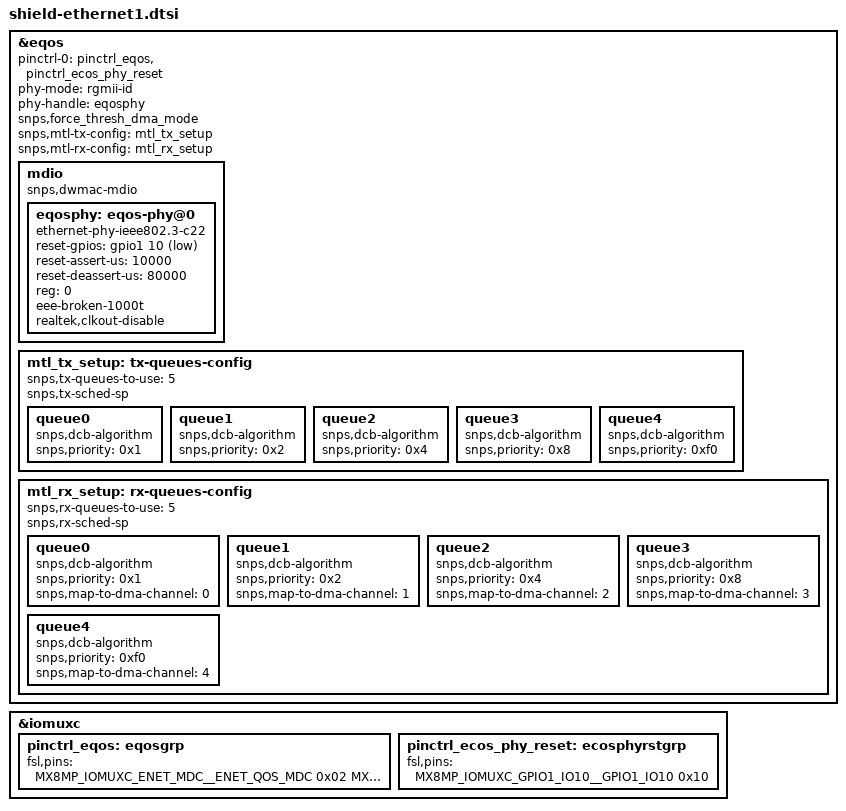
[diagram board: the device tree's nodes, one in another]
// SPDX-License-Identifier: (GPL-2.0+ OR MIT)
/*
 * Copyright 2025 CriticalShift
 */

&eqos {
	pinctrl-names = "default";
	pinctrl-0 = <&pinctrl_eqos>, <&pinctrl_ecos_phy_reset>;
	phy-mode = "rgmii-id";
	phy-handle = <&eqosphy>;
	snps,force_thresh_dma_mode;
	snps,mtl-tx-config = <&mtl_tx_setup>;
	snps,mtl-rx-config = <&mtl_rx_setup>;
	status = "okay";

	mdio {
		compatible = "snps,dwmac-mdio";
		#address-cells = <1>;
		#size-cells = <0>;

		eqosphy: eqos-phy@0 {
			compatible = "ethernet-phy-ieee802.3-c22";
			reset-gpios = <&gpio1 10 GPIO_ACTIVE_LOW>;
			reset-assert-us = <10000>;
			reset-deassert-us = <80000>;
			reg = <0>;
			eee-broken-1000t;
			realtek,clkout-disable;
		};
	};

	mtl_tx_setup: tx-queues-config {
		snps,tx-queues-to-use = <5>;
		snps,tx-sched-sp;
		queue0 {
			snps,dcb-algorithm;
			snps,priority = <0x1>;
		};
		queue1 {
			snps,dcb-algorithm;
			snps,priority = <0x2>;
		};
		queue2 {
			snps,dcb-algorithm;
			snps,priority = <0x4>;
		};
		queue3 {
			snps,dcb-algorithm;
			snps,priority = <0x8>;
		};
		queue4 {
			snps,dcb-algorithm;
			snps,priority = <0xf0>;
		};
	};

	mtl_rx_setup: rx-queues-config {
		snps,rx-queues-to-use = <5>;
		snps,rx-sched-sp;
		queue0 {
			snps,dcb-algorithm;
			snps,priority = <0x1>;
			snps,map-to-dma-channel = <0>;
		};
		queue1 {
			snps,dcb-algorithm;
			snps,priority = <0x2>;
			snps,map-to-dma-channel = <1>;
		};
		queue2 {
			snps,dcb-algorithm;
			snps,priority = <0x4>;
			snps,map-to-dma-channel = <2>;
		};
		queue3 {
			snps,dcb-algorithm;
			snps,priority = <0x8>;
			snps,map-to-dma-channel = <3>;
		};
		queue4 {
			snps,dcb-algorithm;
			snps,priority = <0xf0>;
			snps,map-to-dma-channel = <4>;
		};
	};
};

&iomuxc {
	pinctrl_eqos: eqosgrp {
		fsl,pins = <
			MX8MP_IOMUXC_ENET_MDC__ENET_QOS_MDC					0x02
			MX8MP_IOMUXC_ENET_MDIO__ENET_QOS_MDIO				0x02
			MX8MP_IOMUXC_ENET_RD0__ENET_QOS_RGMII_RD0			0x90
			MX8MP_IOMUXC_ENET_RD1__ENET_QOS_RGMII_RD1			0x90
			MX8MP_IOMUXC_ENET_RD2__ENET_QOS_RGMII_RD2			0x90
			MX8MP_IOMUXC_ENET_RD3__ENET_QOS_RGMII_RD3			0x90
			MX8MP_IOMUXC_ENET_RXC__CCM_ENET_QOS_CLOCK_GENERATE_RX_CLK	0x90
			MX8MP_IOMUXC_ENET_RX_CTL__ENET_QOS_RGMII_RX_CTL		0x90
			MX8MP_IOMUXC_ENET_TD0__ENET_QOS_RGMII_TD0			0x16
			MX8MP_IOMUXC_ENET_TD1__ENET_QOS_RGMII_TD1			0x16
			MX8MP_IOMUXC_ENET_TD2__ENET_QOS_RGMII_TD2			0x16
			MX8MP_IOMUXC_ENET_TD3__ENET_QOS_RGMII_TD3			0x16
			MX8MP_IOMUXC_ENET_TX_CTL__ENET_QOS_RGMII_TX_CTL		0x16
			MX8MP_IOMUXC_ENET_TXC__CCM_ENET_QOS_CLOCK_GENERATE_TX_CLK	0x16
		>;
	};

	pinctrl_ecos_phy_reset: ecosphyrstgrp {
		fsl,pins = <
			MX8MP_IOMUXC_GPIO1_IO10__GPIO1_IO10					0x10
		>;
	};
};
